# MIMXRT1052 register map
Vendor: nxp.com; File version: 1.0
CPU: CM7 r0p1, little endian, MPU, FPU, VTOR, 4 interrupt priority bits
Registers are 32-bit, read-write, reset 0x0 unless marked. A register's access mark holds for its fields unless they carry their own. Offsets are from the block's base; [hi:lo] are bit positions; {n}, {i} and the like mark numbered series; 'fields as' and 'values as' point back to an identical list.

## OCOTP
Base 0x401F4000
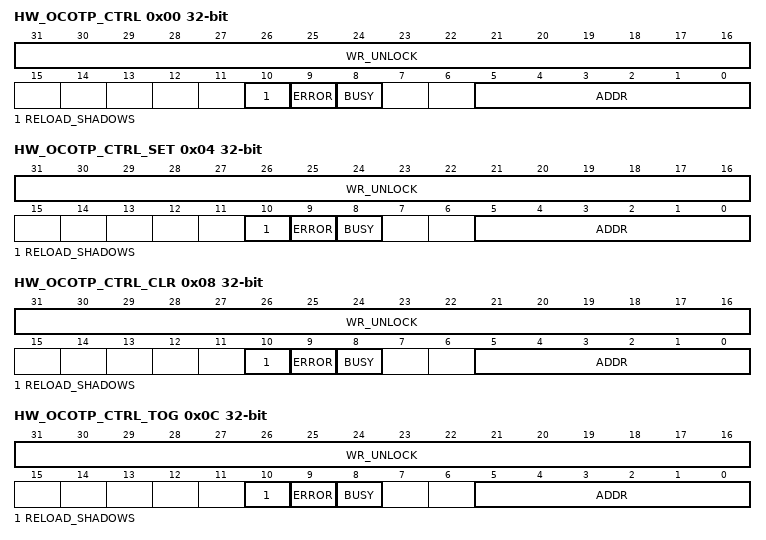
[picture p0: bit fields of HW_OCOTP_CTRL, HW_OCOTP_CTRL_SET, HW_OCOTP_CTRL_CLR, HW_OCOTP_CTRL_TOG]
0x00 HW_OCOTP_CTRL — OTP Controller Control Register
  [31:16] WR_UNLOCK — Write 0x3E77 to enable OTP write accesses
  [10] RELOAD_SHADOWS — Set to force re-loading the shadow registers (HW/SW capability and LOCK)
  [9] ERROR — Set by the controller when an access to a locked region(OTP or shadow register) is requested
  [8] BUSY ro — OTP controller status bit
  [5:0] ADDR — OTP write and read access address register
0x04 HW_OCOTP_CTRL_SET — OTP Controller Control Register
  [31:16] WR_UNLOCK write-1-sets — Write 0x3E77 to enable OTP write accesses
  [10] RELOAD_SHADOWS write-1-sets — Set to force re-loading the shadow registers (HW/SW capability and LOCK)
  [9] ERROR write-1-sets — Set by the controller when an access to a locked region(OTP or shadow register) is requested
  [8] BUSY ro write-1-sets — OTP controller status bit
  [5:0] ADDR write-1-sets — OTP write and read access address register
0x08 HW_OCOTP_CTRL_CLR — OTP Controller Control Register
  [31:16] WR_UNLOCK write-1-clears — Write 0x3E77 to enable OTP write accesses
  [10] RELOAD_SHADOWS write-1-clears — Set to force re-loading the shadow registers (HW/SW capability and LOCK)
  [9] ERROR write-1-clears — Set by the controller when an access to a locked region(OTP or shadow register) is requested
  [8] BUSY ro write-1-clears — OTP controller status bit
  [5:0] ADDR write-1-clears — OTP write and read access address register
0x0C HW_OCOTP_CTRL_TOG — OTP Controller Control Register
  [31:16] WR_UNLOCK write-1-toggles — Write 0x3E77 to enable OTP write accesses
  [10] RELOAD_SHADOWS write-1-toggles — Set to force re-loading the shadow registers (HW/SW capability and LOCK)
  [9] ERROR write-1-toggles — Set by the controller when an access to a locked region(OTP or shadow register) is requested
  [8] BUSY ro write-1-toggles — OTP controller status bit
  [5:0] ADDR write-1-toggles — OTP write and read access address register
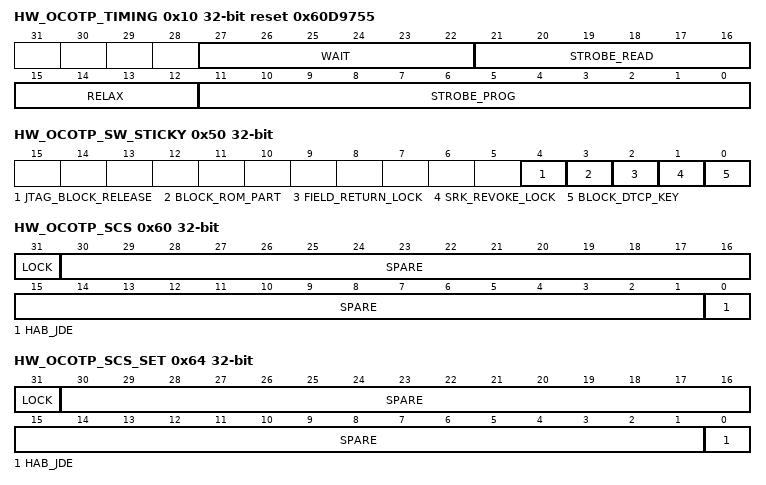
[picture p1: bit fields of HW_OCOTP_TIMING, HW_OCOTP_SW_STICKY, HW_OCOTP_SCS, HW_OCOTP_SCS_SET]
0x10 HW_OCOTP_TIMING reset 0x60D9755 — OTP Controller Timing Register
  [27:22] WAIT — This count value specifies time interval between auto read and write access in one time program
  [21:16] STROBE_READ — This count value specifies the strobe period in one time read OTP
  [15:12] RELAX — This count value specifies the time to add to all default timing parameters other than the Tpgm and Trd
  [11:0] STROBE_PROG — This count value specifies the strobe period in one time write OTP
0x20 HW_OCOTP_DATA — OTP Controller Write Data Register
  [31:0] DATA — Used to initiate a write to OTP
0x30 HW_OCOTP_READ_CTRL — OTP Controller Write Data Register
  [0] READ_FUSE — Used to initiate a read to OTP
0x40 HW_OCOTP_READ_FUSE_DATA — OTP Controller Read Data Register
  [31:0] DATA — The data read from OTP
0x50 HW_OCOTP_SW_STICKY — Sticky bit Register
  [4] JTAG_BLOCK_RELEASE — Set by ARM during Boot after DTCP is initialized and before test mode entry
  [3] BLOCK_ROM_PART — Set by ARM during Boot after DTCP is initialized and before test mode entry, if ROM_PART_LOCK=1
  [2] FIELD_RETURN_LOCK — Shadow register write and OTP write lock for FIELD_RETURN region
  [1] SRK_REVOKE_LOCK — Shadow register write and OTP write lock for SRK_REVOKE region
  [0] BLOCK_DTCP_KEY — Shadow register read and OTP read lock for DTCP_KEY region
0x60 HW_OCOTP_SCS — Software Controllable Signals Register
  [31] LOCK — When set, all of the bits in this register are locked and can not be changed through SW programming
  [30:1] SPARE — Unallocated read/write bits for implementation specific software use.
  [0] HAB_JDE — HAB JTAG Debug Enable
0x64 HW_OCOTP_SCS_SET — Software Controllable Signals Register
  [31] LOCK write-1-sets — When set, all of the bits in this register are locked and can not be changed through SW programming
  [30:1] SPARE write-1-sets — Unallocated read/write bits for implementation specific software use.
  [0] HAB_JDE write-1-sets — HAB JTAG Debug Enable
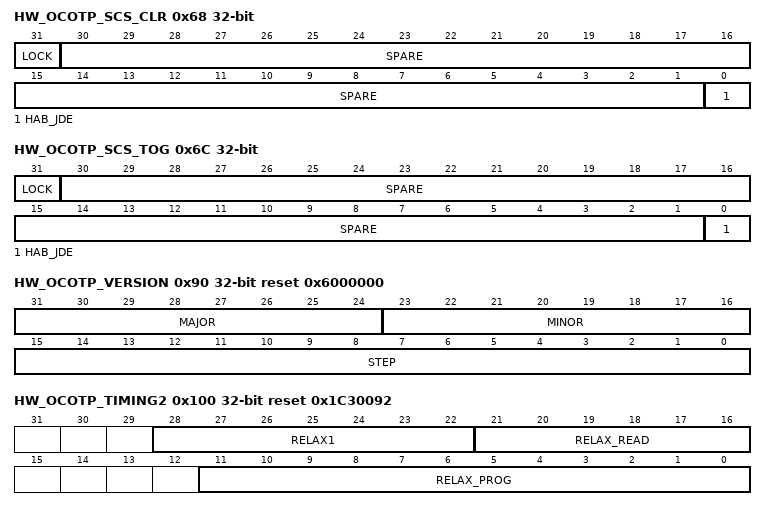
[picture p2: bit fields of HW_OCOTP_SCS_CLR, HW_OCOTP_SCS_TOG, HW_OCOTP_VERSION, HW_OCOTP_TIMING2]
0x68 HW_OCOTP_SCS_CLR — Software Controllable Signals Register
  [31] LOCK write-1-clears — When set, all of the bits in this register are locked and can not be changed through SW programming
  [30:1] SPARE write-1-clears — Unallocated read/write bits for implementation specific software use.
  [0] HAB_JDE write-1-clears — HAB JTAG Debug Enable
0x6C HW_OCOTP_SCS_TOG — Software Controllable Signals Register
  [31] LOCK write-1-toggles — When set, all of the bits in this register are locked and can not be changed through SW programming
  [30:1] SPARE write-1-toggles — Unallocated read/write bits for implementation specific software use.
  [0] HAB_JDE write-1-toggles — HAB JTAG Debug Enable
0x90 HW_OCOTP_VERSION ro reset 0x6000000 — OTP Controller Version Register
  [31:24] MAJOR — Fixed read-only value reflecting the MAJOR field of the RTL version.
  [23:16] MINOR — Fixed read-only value reflecting the MINOR field of the RTL version.
  [15:0] STEP — Fixed read-only value reflecting the stepping of the RTL version.
0x100 HW_OCOTP_TIMING2 reset 0x1C30092 — OTP Controller Timing Register 2
  [28:22] RELAX1 — This count value specifies time interval between auto read and write access in one time program
  [21:16] RELAX_READ — This count value specifies the strobe period in one time read OTP
  [11:0] RELAX_PROG — This count value specifies the strobe period in one time write OTP
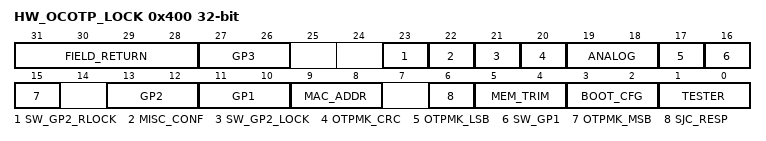
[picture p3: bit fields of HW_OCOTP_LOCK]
0x400 HW_OCOTP_LOCK — Value of OTP Bank0 Word0 (Lock controls)
  [31:28] FIELD_RETURN — Reserved
  [27:26] GP3 ro — Status of shadow register and OTP write lock for gp3 region
  [23] SW_GP2_RLOCK ro — Status of shadow register and OTP read lock for sw_gp2 region
  [22] MISC_CONF ro — Status of shadow register and OTP write lock for misc_conf region
  [21] SW_GP2_LOCK ro — Status of shadow register and OTP write lock for sw_gp2 region
  [20] OTPMK_CRC ro — Status of shadow register and OTP write lock for otpmk_crc region
  [19:18] ANALOG ro — Status of shadow register and OTP write lock for analog region
  [17] OTPMK_LSB ro — Status of shadow register read and write, OTP read and write lock for otpmk region (LSB)
  [16] SW_GP1 ro — Status of shadow register and OTP write lock for sw_gp1 region
  [15] OTPMK_MSB ro — Status of shadow register read and write, OTP read and write lock for otpmk region (MSB)
  [13:12] GP2 ro — Status of shadow register and OTP write lock for gp2 region
  [11:10] GP1 ro — Status of shadow register and OTP write lock for gp1 region
  [9:8] MAC_ADDR ro — Status of shadow register and OTP write lock for mac_addr region
  [6] SJC_RESP ro — Status of shadow register read and write, OTP read and write lock for sjc_resp region
  [5:4] MEM_TRIM ro — Status of shadow register and OTP write lock for mem_trim region
  [3:2] BOOT_CFG ro — Status of shadow register and OTP write lock for boot_cfg region
  [1:0] TESTER ro — Status of shadow register and OTP write lock for tester region
0x410 HW_OCOTP_CFG0 — Value of OTP Bank0 Word1 (Configuration and Manufacturing Info.)
  [31:0] BITS — This register contains 32 bits of the Unique ID and SJC_CHALLENGE field
0x420 HW_OCOTP_CFG1 — Value of OTP Bank0 Word2 (Configuration and Manufacturing Info.)
  fields as HW_OCOTP_CFG0
{0x410+0x10*i} HW_OCOTP_CFG{i} (i=2..6) — Value of OTP Bank0 Word{i+1} (Configuration and Manufacturing Info.)
  [31:0] BITS — Reflects value of OTP Bank 0, word {i+1} (ADDR = {0x1+i})
{0x480+0x10*i} HW_OCOTP_MEM{i} (i=0..4) — Value of OTP Bank1 Word{i} (Memory Related Info.)
  [31:0] BITS — Reflects value of OTP bank 1, word {i} (ADDR = {0x8+i})
{0x4D0+0x10*i} HW_OCOTP_ANA{i} (i=0..2) — Value of OTP Bank1 Word{i+5} (Analog Info.)
  [31:0] BITS — Reflects value of OTP bank 1, word {i+5} (ADDR = {0xD+i})
{0x580+0x10*i} HW_OCOTP_SRK{i} (i=0..7) — Shadow Register for OTP Bank3 Word{i} (SRK Hash)
  [31:0] BITS — Shadow register for the hash of the Super Root Key word{i} (Copy of OTP Bank 3, word {i} (ADDR = {0x1C+i}))
0x600 HW_OCOTP_SJC_RESP0 — Value of OTP Bank4 Word0 (Secure JTAG Response Field)
  [31:0] BITS — Shadow register for the SJC_RESP Key word0 (Copy of OTP Bank 4, word 0 (ADDR = 0x20))
0x610 HW_OCOTP_SJC_RESP1 — Value of OTP Bank4 Word1 (Secure JTAG Response Field)
  [31:0] BITS — Shadow register for the SJC_RESP Key word1 (Copy of OTP Bank 4, word 1 (ADDR = 0x21))
0x620 HW_OCOTP_MAC0 — Value of OTP Bank4 Word2 (MAC Address)
  [31:0] BITS — Reflects value of OTP Bank 4, word 2 (ADDR = 0x22).
0x630 HW_OCOTP_MAC1 — Value of OTP Bank4 Word3 (MAC Address)
  [31:0] BITS — Reflects value of OTP Bank 4, word 3 (ADDR = 0x23).
0x640 HW_OCOTP_GP3 — Value of OTP Bank4 Word4 (MAC Address)
  [31:0] BITS — Reflects value of OTP Bank 4, word 4 (ADDR = 0x24).
0x660 HW_OCOTP_GP1 — Value of OTP Bank4 Word6 (General Purpose Customer Defined Info)
  [31:0] BITS — Reflects value of OTP Bank 4, word 6 (ADDR = 0x26).
0x670 HW_OCOTP_GP2 — Value of OTP Bank4 Word7 (General Purpose Customer Defined Info)
  [31:0] BITS — Reflects value of OTP Bank 4, word 7 (ADDR = 0x27).
0x680 HW_OCOTP_SW_GP1 — Value of OTP Bank5 Word0 (SW GP1)
  [31:0] BITS — Reflects value of OTP Bank 5, word 0 (ADDR = 0x28).
{0x550+0x10*i} HW_OCOTP_SW_GP{i} (i=20..23) — Value of OTP Bank5 Word{i-19} (SW GP2)
  [31:0] BITS — Reflects value of OTP Bank 5, word {i-19} (ADDR = {0x15+i}).
0x6D0 HW_OCOTP_MISC_CONF0 — Value of OTP Bank5 Word5 (Misc Conf)
  [31:0] BITS — Reflects value of OTP Bank 5, word 5 (ADDR = 0x2d).
0x6E0 HW_OCOTP_MISC_CONF1 — Value of OTP Bank5 Word6 (Misc Conf)
  [31:0] BITS — Reflects value of OTP Bank 5, word 6 (ADDR = 0x2e).
0x6F0 HW_OCOTP_SRK_REVOKE — Value of OTP Bank5 Word7 (SRK Revoke)
  [31:0] BITS — Reflects value of OTP Bank 5, word 7 (ADDR = 0x2f).
